# AT32UC3A0256 device description
Architecture: AVR32_UC3; Family: AVR UC3
Registers are 32-bit, read-write, reset 0x0 unless marked. A register's access mark holds for its fields unless they carry their own. Offsets are from the block's base; [hi:lo] are bit positions; lines under a group give offsets from that group; {n}, {i} and the like mark numbered series.

## GPIO — General Purpose Input/Output
Instances: GPIO 0xffff1000
{0x0+0x100*i} port[{i}] (i=0..63) group
  0x00 GPER — GPIO Enable Register
  0x04 GPERS wo reset not defined — GPIO Enable Register - Set
  0x08 GPERC wo reset not defined — GPIO Enable Register - Clear
  0x0C GPERT wo reset not defined — GPIO Enable Register - Toggle
  0x10 PMR0 — Peripheral Mux Register 0
  0x14 PMR0S wo reset not defined — Peripheral Mux Register 0 - Set
  0x18 PMR0C wo reset not defined — Peripheral Mux Register 0 - Clear
  0x1C PMR0T wo reset not defined — Peripheral Mux Register 0 - Toggle
  0x20 PMR1 — Peripheral Mux Register 1
  0x24 PMR1S wo reset not defined — Peripheral Mux Register 1 - Set
  0x28 PMR1C wo reset not defined — Peripheral Mux Register 1 - Clear
  0x2C PMR1T wo reset not defined — Peripheral Mux Register 1 - Toggle
  0x40 ODER — Output Driver Enable Register
  0x44 ODERS wo reset not defined — Output Driver Enable Register - Set
  0x48 ODERC wo reset not defined — Output Driver Enable Register - Clear
  0x4C ODERT wo reset not defined — Output Driver Enable Register - Toggle
  0x50 OVR — Output Value Register
  0x54 OVRS wo reset not defined — Output Value Register - Set
  0x58 OVRC wo reset not defined — Output Value Register - Clear
  0x5C OVRT wo reset not defined — Output Value Register - Toggle
  0x60 PVR ro — Pin Value Register
  0x70 PUER — Pull-up Enable Register
  0x74 PUERS wo reset not defined — Pull-up Enable Register - Set
  0x78 PUERC wo reset not defined — Pull-up Enable Register - Clear
  0x7C PUERT wo reset not defined — Pull-up Enable Register - Toggle
  0x80 ODMER — Open Drain Mode Register
  0x84 ODMERS wo reset not defined — Open Drain Mode Register - Set
  0x88 ODMERC wo reset not defined — Open Drain Mode Register - Clear
  0x8C ODMERT wo reset not defined — Open Drain Mode Register - Toggle
  0x90 IER — Interrupt Enable Register
  0x94 IERS wo reset not defined — Interrupt Enable Register - Set
  0x98 IERC wo reset not defined — Interrupt Enable Register - Clear
  0x9C IERT wo reset not defined — Interrupt Enable Register - Toggle
  0xA0 IMR0 — Interrupt Mode Register 0
  0xA4 IMR0S wo reset not defined — Interrupt Mode Register 0 - Set
  0xA8 IMR0C wo reset not defined — Interrupt Mode Register 0 - Clear
  0xAC IMR0T wo reset not defined — Interrupt Mode Register 0 - Toggle
  0xB0 IMR1 — Interrupt Mode Register 1
  0xB4 IMR1S wo reset not defined — Interrupt Mode Register 1 - Set
  0xB8 IMR1C wo reset not defined — Interrupt Mode Register 1 - Clear
  0xBC IMR1T wo reset not defined — Interrupt Mode Register 1 - Toggle
  0xC0 GFER — Glitch Filter Enable Register
  0xC4 GFERS wo reset not defined — Glitch Filter Enable Register - Set
  0xC8 GFERC wo reset not defined — Glitch Filter Enable Register - Clear
  0xCC GFERT wo reset not defined — Glitch Filter Enable Register - Toggle
  0xD0 IFR ro — Interrupt Flag Register
  0xD8 IFRC wo reset not defined — Interrupt Flag Register - Clear

## HMATRIX — HSB Matrix
Instances: HMATRIX 0xfffe1000
{0x0+4i} mcfg[{i}] (i=0..15) access not given reset not defined
  [2:0] ULBT — Undefined Length Burst Type
    0=INFINITE; 1=SINGLE; 2=FOUR_BEAT; 3=EIGHT_BEAT; 4=SIXTEEN_BEAT
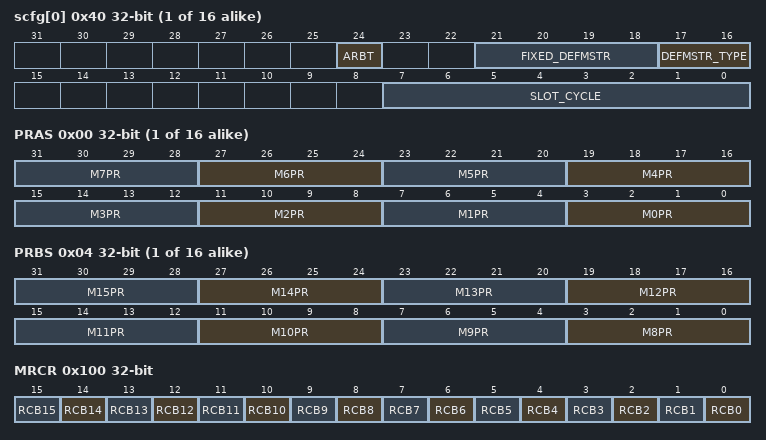
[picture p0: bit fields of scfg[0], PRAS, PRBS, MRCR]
{0x40+4i} scfg[{i}] (i=0..15) access not given reset not defined
  [24] ARBT — Arbitration Type
    0=ROUND_ROBIN; 1=FIXED_PRIORITY
  [21:18] FIXED_DEFMSTR — Fixed Index of Default Master
  [17:16] DEFMSTR_TYPE — Default Master Type
    0=NO_DEFAULT; 1=LAST_DEFAULT; 2=FIXED_DEFAULT
  [7:0] SLOT_CYCLE — Maximum Number of Allowed Cycles for a Burst
{0x80+8i} prs[{i}] (i=0..15) group
  0x00 PRAS — Priority Register A for Slave 0
    [4n+3:4n] M{n}PR (n=0..7) — Master {n} Priority
  0x04 PRBS — Priority Register B for Slave 0
    [4n-29:4n-32] M{n}PR (n=8..15) — Master {n} Priority
0x100 MRCR — Master Remap Control Register
  [n] RCB{n} (n=0..15) — Remap Command bit for Master {n}
{0x110+4i} sfr[{i}] (i=0..15) access not given
  [31:0] SFR — Special Function Register
